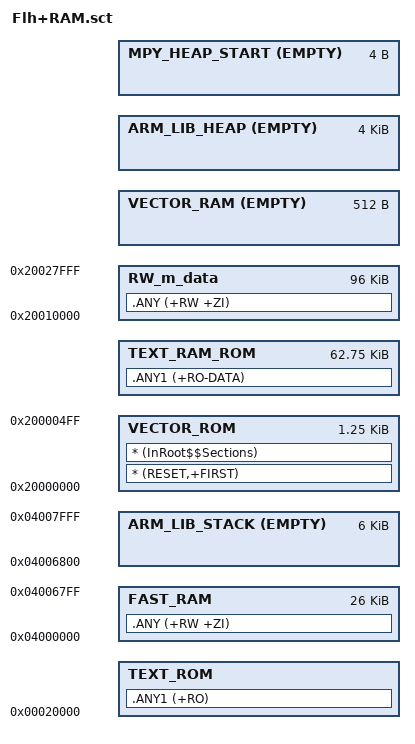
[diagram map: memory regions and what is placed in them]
#! armcc -E

#define STACK_SIZE 0x1800
#define RAM_ROM1_BASE	0x20000000
#define RAM_ROM1_SIZE	64*1024
; must use "VECTOR_RAM", "RW_m_data", "VECTOR_ROM" as names to work with "InstallIRQHandler()" API



LR_RAM_ROM1 RAM_ROM1_BASE RAM_ROM1_SIZE {
	  VECTOR_ROM +0 0x500 { ; vector table
		* (RESET,+FIRST)
		* (InRoot$$Sections)
	  }

	  TEXT_RAM_ROM +0 RAM_ROM1_SIZE-0x500  {
	  	.ANY1 (+RO-DATA)	// high priority
	  }
	  
}

LR_IROM2 0x00020000 384*1024 {
	  TEXT_ROM +0 { ; load address = execution address
		.ANY1 (+RO)
	  }

  ; >>> RAMX regions
	  ; RAM vector table, unless "InstallIRQHandler()" is called, not used

	  FAST_RAM 0x04000000 32*1024- STACK_SIZE {
		 .ANY (+RW +ZI)
	  }
	  
	  ARM_LIB_STACK 0x04008000-STACK_SIZE EMPTY STACK_SIZE { ; Stack region growing down
	  }

  ; <<<
  
  ; >>> AHB RAM (2 cycles access) regions, main R/W
	  RW_m_data RAM_ROM1_BASE+RAM_ROM1_SIZE (64+64+32)*1024-RAM_ROM1_SIZE { ; RW data
		.ANY (+RW +ZI)
	  }
	  VECTOR_RAM +0 EMPTY 0x200 { ; RAM vector region (in RAMX)
	  } 
	  ARM_LIB_HEAP +0 EMPTY 0x1000 ; Heap region growing up
      {}
	  MPY_HEAP_START +0 EMPTY 4 {
	  }
  ; <<<
  
  ; >>> SDRAM >>>
	  ;RW_FB 0xA0000000 EMPTY UNINIT 1024*1024  {
	  ;}
	  
	  ;RW_SDRAM 0xA0100000 EMPTY UNINIT (32-1)*1024*1024  {
	  ;}
; <<<
}
